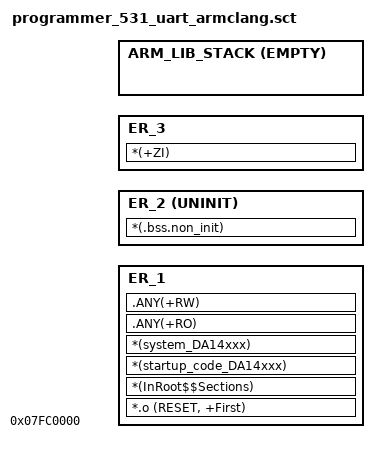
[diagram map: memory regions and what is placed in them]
#! armclang -E -I.\..\..\sdk\platform\include\ --target=arm-arm-none-eabi -mcpu=cortex-m0plus -xc

#define __DA14531__
#include "sdk_defs.h"

LR_1 0x07FC0000 15*1024 {
    ER_1 +0 {
       *.o (RESET, +First)
       *(InRoot$$Sections)
        *(startup_code_DA14xxx)
       *(system_DA14xxx)
       .ANY(+RO)
       .ANY(+RW)
    }

    ER_2 AlignExpr(+0,8) UNINIT {
       *(.bss.non_init)
    }

; ***************************************************************************
; Calculated values for DA14531 based on `sdk_defs.h` header file input.
; SDK_RAM_UNINIT_START_ADDRESS    = 0x07FCB000
; SDK_RAM_UNINIT_END_ADDRESS      = 0x07FCBA00
; ***************************************************************************

; ***************************************************************************
; The RAM space from address 0x07FCB000 to 0x07FCBA00 must not be used by the
; flash programmer and must remain uninitialized, in order to be used by the
; TRNG software mechanism of the RAM downloaded application. The buffer used
; by the TRNG software mechanism must be fed with random data in order to
; generate true random seeds.
; ***************************************************************************
    ER_3 +0 (SDK_RAM_UNINIT_START_ADDRESS - ImageLimit(ER_2)) {
        *(+ZI)
    }

    ; Stack region growing down
    ARM_LIB_STACK SDK_RAM_END_ADDR EMPTY -(SDK_RAM_END_ADDR - SDK_RAM_UNINIT_END_ADDRESS) {}
}
